AUTOSAR XML (schema 4-2-2)
package /Components
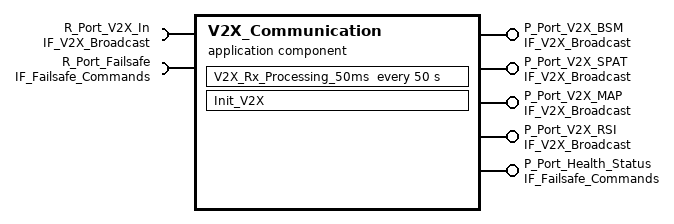
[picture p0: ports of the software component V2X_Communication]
  application sw component type V2X_Communication
    5 x provide port:
      P_Port_V2X_BSM: provided-interface=IF_V2X_Broadcast
      P_Port_V2X_SPAT: provided-interface=IF_V2X_Broadcast
      P_Port_V2X_MAP: provided-interface=IF_V2X_Broadcast
      P_Port_V2X_RSI: provided-interface=IF_V2X_Broadcast
      P_Port_Health_Status: provided-interface=IF_Failsafe_Commands
    require port R_Port_V2X_In: required-interface=IF_V2X_Broadcast
    require port R_Port_Failsafe: required-interface=IF_Failsafe_Commands
    behavior V2X_Communication_InternalBehavior
      data received event V2X_Frame_Received: start-on-event=V2X_Rx_Processing_50ms
      timing event V2X_50ms: start-on-event=V2X_Rx_Processing_50ms, period=50
      runnable Init_V2X
        data-receive-point-by-arguments:
          access Read_Failsafe_Status: accessed-variable=R_Port_Failsafe.Failsafe_Status
        data-send-points:
          access Send_Health_Status: accessed-variable=P_Port_Health_Status.Failsafe_Status
        parameter access InitParamAccess_V2X_Broadcast: accessed-parameter=P_Port_V2X_BSM.BSM
      runnable V2X_Rx_Processing_50ms: minimum-start-interval=50
        data-receive-point-by-arguments:
          6 x access:
            Read_BSM_In: accessed-variable=R_Port_V2X_In.BSM
            Read_SPAT_In: accessed-variable=R_Port_V2X_In.SPaT
            Read_MAP_In: accessed-variable=R_Port_V2X_In.MAP
            Read_RSI_In: accessed-variable=R_Port_V2X_In.RSI
            Read_MRC_Command: accessed-variable=R_Port_Failsafe.MRC_Command
            Read_SOS_Command: accessed-variable=R_Port_Failsafe.SOS_Command
        data-send-points:
          4 x access:
            Send_BSM: accessed-variable=P_Port_V2X_BSM.BSM
            Send_SPAT: accessed-variable=P_Port_V2X_SPAT.SPaT
            Send_MAP: accessed-variable=P_Port_V2X_MAP.MAP
            Send_RSI: accessed-variable=P_Port_V2X_RSI.RSI
        parameter access RuntimeParamAccess_SPAT_Rate: accessed-parameter=P_Port_V2X_SPAT.SPaT
